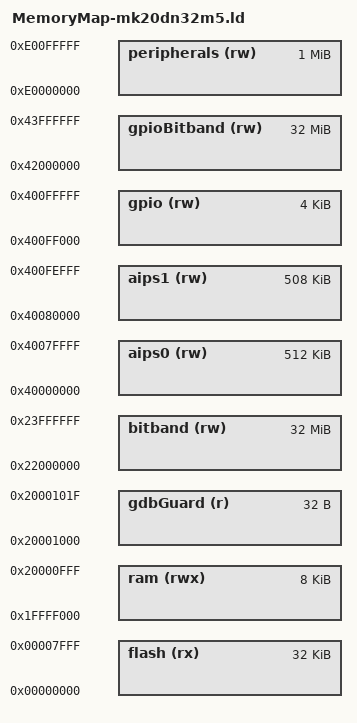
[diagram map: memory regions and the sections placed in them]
/* MemoryMap-sramu.ld
 *
 * Memory map for devices with SRAM_U allocation for bit-band/bme
 */
 
/* ---- <<< Use Configuration Wizard in Context Menu >>> ---- */

/* <o> Stack Size
   <i> Required amount of stack space
   <i> In CMSIS this will determine the ISR stack size
   <0x0-0x2000> 
*/
__stack_size = 0x800;

/* <o> Minimum Heap Size 
   <i> Actual heap may be larger as it fills all unused RAM up to STACK
   <0x0-0x2000> 
*/
__heap_size  = 0x800;

/* <o0> Size of RAM region reserved for bit-band or bit-manipulation-engine (bytes) 
   <i>  Space is allocated in SRAM_U memory region
   <i>  Each byte as also mapped to 8 words in .bitband memory region (if present)
   <i>
   <i>  C Example:
   <i>    // Variable allocated in bitband/bme accessible region (SRAM_U)
   <i>    // May be uint8_t, uint16_t or uint32_t
   <i>    __attribute__ ((section(".sram_u"))) uint32_t variable;
   <i>
   <i>    // Each word of array maps to an individual bit in bit-band
   <i>    __attribute__ ((section(".bitband"))) uint32_t variable_bits[8*sizeof(variable)];
   <i>
   <i>  See bme.h and bitband.h for more information
*/
__sram_u_size = 0;
   
/*
 * Memory Map generated by USBDM New Project Wizard for MK20DN32M5
 */
MEMORY
{
  bitband        (rw)  : ORIGIN = 0x22000000, LENGTH = 0x02000000
  aips0          (rw)  : ORIGIN = 0x40000000, LENGTH = 0x00080000
  aips1          (rw)  : ORIGIN = 0x40080000, LENGTH = 0x0007F000
  gpio           (rw)  : ORIGIN = 0x400FF000, LENGTH = 0x00001000
  gpioBitband    (rw)  : ORIGIN = 0x42000000, LENGTH = 0x02000000
  peripherals    (rw)  : ORIGIN = 0xE0000000, LENGTH = 0x00100000
/*
 *  <o>  FLASH  address <constant>
 *  <o1> FLASH  size    <constant>
 */
  flash          (rx)  : ORIGIN = 0x00000000, LENGTH = 0x00008000
/*
 *  <o>  RAM    address <constant>
 *  <o1> RAM    size    <constant>
 */
  ram            (rwx) : ORIGIN = 0x1FFFF000, LENGTH = 0x00002000
  /* Guard region above stack for GDB */
  gdbGuard       (r)   : ORIGIN = 0x20001000, LENGTH = 0x00000020
};


